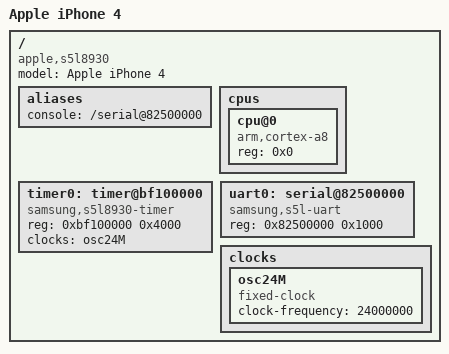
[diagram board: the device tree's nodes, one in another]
/dts-v1/;
/* #include "skeleton.dtsi" */

/ {

	model = "Apple iPhone 4";
	compatible = "apple,s5l8930";
	#address-cells = <1>;
	#size-cells = <1>;

	aliases {
		console = "/serial@82500000";
	};

	cpus {
		#address-cells = <1>;
		#size-cells = <0>;

		cpu@0 {
			device_type = "cpu";
			compatible = "arm,cortex-a8";
			reg = <0x0>;
		};
	};

	timer0: timer@bf100000 {
		compatible = "samsung,s5l8930-timer";
		reg = <0xbf100000 0x4000>;
		clocks = <&osc24M>;
	};	

	uart0: serial@82500000 {
		compatible = "samsung,s5l-uart";
		reg = <0x82500000 0x1000>;
	};


	clocks {
		#address-cells = <1>;
		#size-cells = <1>;
		ranges;

		osc24M: osc24M {
			#clock-cells = <0>;
			compatible = "fixed-clock";
			clock-frequency = <24000000>;
		};
	};

};
